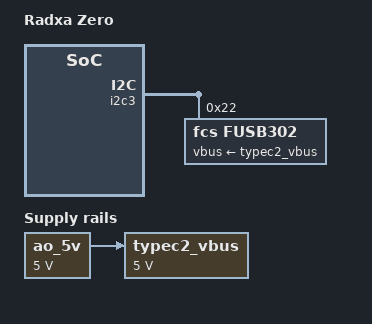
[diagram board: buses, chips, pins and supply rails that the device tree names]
#include "g12a_s905y2_2g.dts"

/{
	model = "Radxa Zero";
	coreelec-dt-id = "g12a_s905y2_radxa_zero";

	/delete-node/ memory@00000000;
	/delete-node/ meson-ir;
	/delete-node/ meson-remote;

	typec2_vbus: regulator-typec2_vbus {
		compatible = "regulator-fixed";
		regulator-name = "TYPEC2_VBUS";
		regulator-min-microvolt = <5000000>;
		regulator-max-microvolt = <5000000>;
		vin-supply = <&ao_5v>;
		regulator-boot-on;
		regulator-always-on;
	};

	ao_5v: regulator-ao_5v {
		compatible = "regulator-fixed";
		regulator-name = "AO_5V";
		regulator-min-microvolt = <5000000>;
		regulator-max-microvolt = <5000000>;
		regulator-boot-on;
		regulator-always-on;
	};
};

&pinctrl_aobus {
	/* Ensure the TYPE C controller irq pin is not driven by the SoC */
	fusb302_irq_pins: fusb302_irq {
		mux {
			groups = "GPIOAO_5";
			function = "gpio_aobus";
			bias-pull-up;
			output-disable;
		};
	};
};

&i2c3 {
	status = "okay";

	fusb302@22 {
		compatible = "fcs,fusb302";
		reg = <0x22>;

		pinctrl-0 = <&fusb302_irq_pins>;
		pinctrl-names = "default";
		interrupt-parent = <&gpio_intc>;
		interrupts = <5 IRQ_TYPE_LEVEL_LOW>;

		vbus-supply = <&typec2_vbus>;

		status = "okay";

		connector {
			compatible = "usb-c-connector";
			power-role = "dual";
			pd-disable;
			self-powered;
			typec-power-opmode = "default";
			try-power-role = "source";
		};
	};
};
